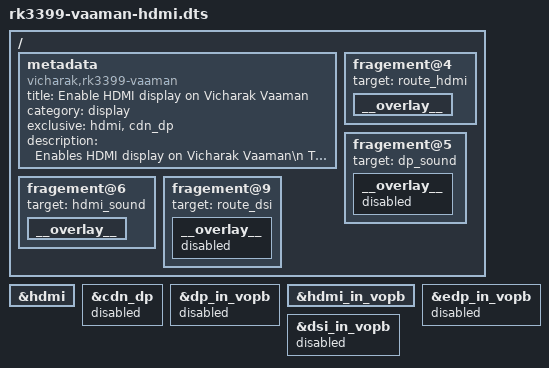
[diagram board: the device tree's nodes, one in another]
// SPDX-License-Identifier: GPL-2.0+
// Copyright (C) 2023 Vicharak Computers LLP

/dts-v1/;
/plugin/;

/ {
	metadata {
		title = "Enable HDMI display on Vicharak Vaaman";
		compatible = "vicharak,rk3399-vaaman", "rockchip,rk3399";
		category = "display";
		exclusive = "hdmi, cdn_dp";
		description = "Enables HDMI display on Vicharak Vaaman\n This will enable HDMI port while disabling CDN_DP if enabled.\nThis is required due to the hardware limitation of RK3399 VOP";
	};

	fragment@0 {
		target = <&hdmi>;

		__overlay__ {
			status = "okay";
		};
	};

	fragment@1 {
		target = <&cdn_dp>;

		__overlay__ {
			status = "disabled";
		};
	};

	fragment@2 {
		target = <&dp_in_vopb>;

		__overlay__ {
			status = "disabled";
		};
	};

	fragment@3 {
		target = <&hdmi_in_vopb>;

		__overlay__ {
			status = "okay";
		};
	};

	fragement@4 {
		target = <&route_hdmi>;

		__overlay__ {
			status = "okay";
		};
	};

	fragement@5 {
		target = <&dp_sound>;

		__overlay__ {
			status = "disabled";
		};
	};

	fragement@6 {
		target = <&hdmi_sound>;

		__overlay__ {
			status = "okay";
		};
	};

	fragment@7 {
		target = <&edp_in_vopb>;

		__overlay__ {
			status = "disabled";
		};
	};

	fragment@8 {
		target = <&dsi_in_vopb>;

		__overlay__ {
			status = "disabled";
		};
	};

	fragement@9 {
		target = <&route_dsi>;

		__overlay__ {
			status = "disabled";
		};
	};
};
